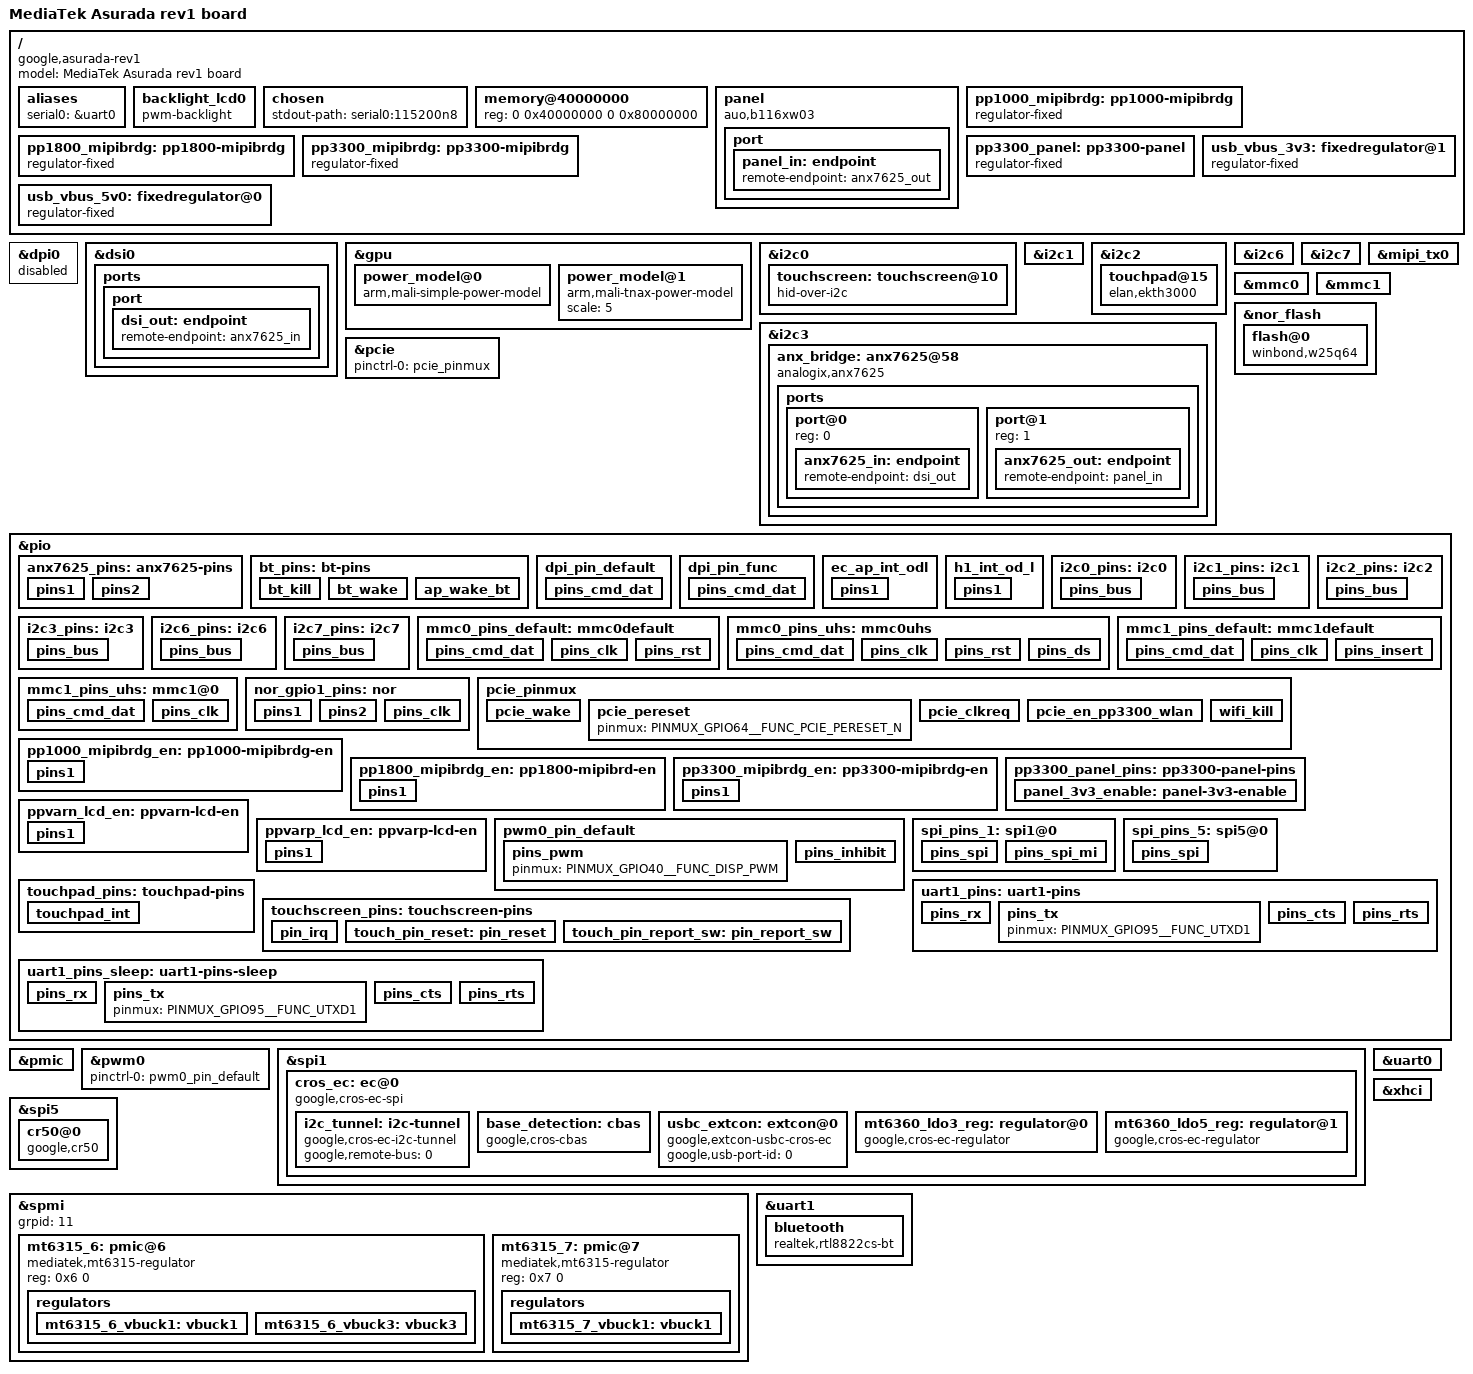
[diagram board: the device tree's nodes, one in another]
// SPDX-License-Identifier: (GPL-2.0 OR MIT)
/*
 * Copyright (C) 2020 MediaTek Inc.
 * Author: Seiya Wang <seiya.wang@mediatek.com>
 */
/dts-v1/;
#include <dt-bindings/gpio/gpio.h>
#include "mt8192.dtsi"
#include "mt6359.dtsi"

/ {
	model = "MediaTek Asurada rev1 board";
	compatible = "google,asurada-rev1", "google,asurada", "mediatek,mt6873";

	aliases {
		serial0 = &uart0;
	};

	backlight_lcd0: backlight_lcd0 {
		compatible = "pwm-backlight";
		pwms = <&pwm0 0 500000>;
		enable-gpios = <&pio 152 0>;
		brightness-levels = < 0 1023 >;
		num-interpolated-steps = <1023>;
		default-brightness-level = <576>;
		status = "okay";
	};

	chosen {
		stdout-path = "serial0:115200n8";
	};

	memory@40000000 {
		device_type = "memory";
		reg = <0 0x40000000 0 0x80000000>;
	};

	panel: panel {
		compatible = "auo,b116xw03";
		power-supply = <&pp3300_panel>;
		ddc-i2c-bus = <&i2c3>;
		backlight = <&backlight_lcd0>;

		port {
			panel_in: endpoint {
				remote-endpoint = <&anx7625_out>;
			};
		};
	};

	pp1000_mipibrdg: pp1000-mipibrdg {
		compatible = "regulator-fixed";
		regulator-name = "pp1000_mipibrdg";
		pinctrl-names = "default";
		pinctrl-0 = <&pp1000_mipibrdg_en>;

		enable-active-high;
		regulator-always-on;

		gpio = <&pio 129 GPIO_ACTIVE_HIGH>;
	};

	pp1800_mipibrdg: pp1800-mipibrdg {
		compatible = "regulator-fixed";
		regulator-name = "pp1800_mipibrdg";
		pinctrl-names = "default";
		pinctrl-0 = <&pp1800_mipibrdg_en>;

		enable-active-high;
		regulator-always-on;

		gpio = <&pio 128 GPIO_ACTIVE_HIGH>;
	};

	pp3300_mipibrdg: pp3300-mipibrdg {
		compatible = "regulator-fixed";
		regulator-name = "pp3300_mipibrdg";
		pinctrl-names = "default";
		pinctrl-0 = <&pp3300_mipibrdg_en>;

		enable-active-high;
		regulator-always-on;

		gpio = <&pio 127 GPIO_ACTIVE_HIGH>;
	};

	/* Probably useless, as we use pp3300_mipibrdg for panel power */
	pp3300_panel: pp3300-panel {
		compatible = "regulator-fixed";
		regulator-name = "pp3300_panel";
		regulator-min-microvolt = <3300000>;
		regulator-max-microvolt = <3300000>;
		pinctrl-names = "default";
		pinctrl-0 = <&pp3300_panel_pins>;

		enable-active-high;
		regulator-always-on;

		gpio = <&pio 136 GPIO_ACTIVE_HIGH>;
	};

	usb_vbus_3v3: fixedregulator@1 {
		compatible = "regulator-fixed";
		regulator-name = "usb vbus";
		regulator-min-microvolt = <3300000>;
		regulator-max-microvolt = <3300000>;
		regulator-always-on;
	};

	usb_vbus_5v0: fixedregulator@0 {
		compatible = "regulator-fixed";
		regulator-name = "vbus";
		regulator-min-microvolt = <5000000>;
		regulator-max-microvolt = <5000000>;
		regulator-type = "voltage";
		regulator-always-on;
	};
};

&dpi0 {
	pinctrl-names = "sleep", "default";
	pinctrl-0 = <&dpi_pin_default>;
	pinctrl-1 = <&dpi_pin_func>;
	status = "disabled";
};

&dsi0 {
	status = "okay";
	#address-cells = <1>;
	#size-cells = <0>;

	ports {
		port {
			dsi_out: endpoint {
				remote-endpoint = <&anx7625_in>;
			};
		};
	};
};

&gpu {
	supply-names = "mali","mali_sram";
	mali-supply = <&mt6315_7_vbuck1>;
	mali_sram-supply = <&mt6359_vsram_others_ldo_reg>;
	operating-points-v2 = <&gpu_opp_table>;
	power_model@0 {
		compatible = "arm,mali-simple-power-model";
		static-coefficient = <2427750>;
		dynamic-coefficient = <4687>;
		ts = <20000 2000 (-20) 2>;
		thermal-zone = "cpu_thermal";
	};
	power_model@1 {
		compatible = "arm,mali-tnax-power-model";
		scale = <5>;
	};
};

&i2c0 {
	pinctrl-names = "default";
	pinctrl-0 = <&i2c0_pins>;
	status = "okay";
	clock-frequency = <100000>;

	touchscreen: touchscreen@10 {
		compatible = "hid-over-i2c";
		reg = <0x10>;
		interrupt-parent = <&pio>;
		interrupts = <21 IRQ_TYPE_LEVEL_LOW>;

		pinctrl-names = "default";
		pinctrl-0 = <&touchscreen_pins>;

		post-power-on-delay-ms = <10>;
		hid-descr-addr = <0x0001>;
	};
};

&i2c1 {
	pinctrl-names = "default";
	pinctrl-0 = <&i2c1_pins>;
	status = "okay";
	clock-frequency = <100000>;

	/* TODO: Add audio components */
};

&i2c2 {
	pinctrl-names = "default";
	pinctrl-0 = <&i2c2_pins>;
	status = "okay";
	clock-frequency = <100000>;

	touchpad@15 {
		compatible = "elan,ekth3000";
		reg = <0x15>;

		pinctrl-names = "default";
		pinctrl-0 = <&touchpad_pins>;

		interrupt-parent = <&pio>;
		interrupts = <15 IRQ_TYPE_LEVEL_LOW>;

		wakeup-source;
	};

};

&i2c3 {
	pinctrl-names = "default";
	pinctrl-0 = <&i2c3_pins>;
	status = "okay";
	clock-frequency = <100000>;

	anx_bridge: anx7625@58 {
		compatible = "analogix,anx7625";
		reg = <0x58>;
		pinctrl-names = "default";
		pinctrl-0 = <&anx7625_pins>;
		panel_flags = <1>;
		enable-gpios = <&pio 41 GPIO_ACTIVE_HIGH>;
		reset-gpios = <&pio 42 GPIO_ACTIVE_HIGH>;
		vdd10-supply = <&pp1000_mipibrdg>;
		vdd18-supply = <&pp1800_mipibrdg>;
		vdd33-supply = <&pp3300_mipibrdg>;

		ports {
			#address-cells = <1>;
			#size-cells = <0>;
			port@0 {
				reg = <0>;
				anx7625_in: endpoint {
					remote-endpoint = <&dsi_out>;
				};
			};

			port@1 {
				reg = <1>;
				anx7625_out: endpoint {
					remote-endpoint = <&panel_in>;
				};
			};
		};
	};
};

&i2c6 {
	pinctrl-names = "default";
	pinctrl-0 = <&i2c6_pins>;
	status = "okay";
	clock-frequency = <100000>;

	/* TODO: Add SAR sensor. */
};

&i2c7 {
	pinctrl-names = "default";
	pinctrl-0 = <&i2c7_pins>;
	status = "okay";
	clock-frequency = <100000>;

	/* TODO: Add ANX7625 external DP bridge. */
};

&mipi_tx0 {
	status = "okay";
};

&mmc0 {
	status = "okay";
	pinctrl-names = "default", "state_uhs";
	pinctrl-0 = <&mmc0_pins_default>;
	pinctrl-1 = <&mmc0_pins_uhs>;
	bus-width = <8>;
	max-frequency = <200000000>;
	cap-mmc-highspeed;
	mmc-hs200-1_8v;
	mmc-hs400-1_8v;
	supports-cqe;
	cap-mmc-hw-reset;
	hs400-ds-delay = <0x12814>;
	no-sdio;
	no-sd;
	vmmc-supply = <&mt6359_vemc_1_ldo_reg>;
	vqmmc-supply = <&mt6359_vufs_ldo_reg>;
	non-removable;
};

&mmc1 {
	status = "okay";
	pinctrl-names = "default", "state_uhs";
	pinctrl-0 = <&mmc1_pins_default>;
	pinctrl-1 = <&mmc1_pins_uhs>;
	bus-width = <4>;
	max-frequency = <200000000>;
	cap-sd-highspeed;
	sd-uhs-sdr50;
	sd-uhs-sdr104;
	cd-gpios = <&pio 17 GPIO_ACTIVE_LOW>;
	vmmc-supply = <&mt6360_ldo5_reg>;
	vqmmc-supply = <&mt6360_ldo3_reg>;
	no-mmc;
	no-sdio;
};

&nor_flash {
	status = "okay";
	pinctrl-names = "default";
	pinctrl-0 = <&nor_gpio1_pins>;
	assigned-clocks = <&topckgen CLK_TOP_SFLASH_SEL>;
	assigned-clock-parents = <&topckgen CLK_TOP_UNIVPLL_D6_D8>;

	flash@0 {
		compatible = "winbond,w25q64", "jedec,spi-nor";
		reg = <0>;
		spi-max-frequency = <52000000>;
		spi-rx-bus-width = <2>;
		spi-tx-bus-width = <2>;
	};
};

&pcie {
	status = "okay";
	pinctrl-names = "default";
	pinctrl-0 = <&pcie_pinmux>;
};

&pio {
	anx7625_pins: anx7625-pins {
		pins1 {
			pinmux = <PINMUX_GPIO41__FUNC_GPIO41>,
				 <PINMUX_GPIO42__FUNC_GPIO42>;
			output-low;
		};
		pins2 {
			pinmux = <PINMUX_GPIO6__FUNC_GPIO6>;
			input-enable;
			bias-pull-up;
		};
	};

	bt_pins: bt-pins {
		bt_kill: bt_kill {
			pinmux = <PINMUX_GPIO131__FUNC_GPIO131>; /* BT_KILL_L */
			output-low;
		};
		bt_wake: bt_wake {
			pinmux = <PINMUX_GPIO22__FUNC_GPIO22>;  /* bt to wake ap */
			bias-pull-up;
		};
		ap_wake_bt: ap_wake_bt {
			pinmux = <PINMUX_GPIO168__FUNC_GPIO168>; /* AP_WAKE_BT_L */
			output-low;
		};
	};

	dpi_pin_default: dpi_pin_default {
		pins_cmd_dat {
			pinmux = <PINMUX_GPIO96__FUNC_GPIO96>,
				<PINMUX_GPIO97__FUNC_GPIO97>,
				<PINMUX_GPIO98__FUNC_GPIO98>,
				<PINMUX_GPIO99__FUNC_GPIO99>,
				<PINMUX_GPIO100__FUNC_GPIO100>,
				<PINMUX_GPIO101__FUNC_GPIO101>,
				<PINMUX_GPIO102__FUNC_GPIO102>,
				<PINMUX_GPIO103__FUNC_GPIO103>,
				<PINMUX_GPIO104__FUNC_GPIO104>,
				<PINMUX_GPIO105__FUNC_GPIO105>,
				<PINMUX_GPIO106__FUNC_GPIO106>,
				<PINMUX_GPIO110__FUNC_GPIO110>,
				<PINMUX_GPIO113__FUNC_GPIO113>,
				<PINMUX_GPIO111__FUNC_GPIO111>,
				<PINMUX_GPIO109__FUNC_GPIO109>,
				<PINMUX_GPIO112__FUNC_GPIO112>;
				drive-strength = <MTK_DRIVE_6mA>;
				output-low;
		};
	};

	dpi_pin_func: dpi_pin_func {
		pins_cmd_dat {
			pinmux = <PINMUX_GPIO96__FUNC_DPI_D0>,
				<PINMUX_GPIO97__FUNC_DPI_D1>,
				<PINMUX_GPIO98__FUNC_DPI_D2>,
				<PINMUX_GPIO99__FUNC_DPI_D3>,
				<PINMUX_GPIO100__FUNC_DPI_D4>,
				<PINMUX_GPIO101__FUNC_DPI_D5>,
				<PINMUX_GPIO102__FUNC_DPI_D6>,
				<PINMUX_GPIO103__FUNC_DPI_D7>,
				<PINMUX_GPIO104__FUNC_DPI_D8>,
				<PINMUX_GPIO105__FUNC_DPI_D9>,
				<PINMUX_GPIO106__FUNC_DPI_D10>,
				<PINMUX_GPIO110__FUNC_DPI_D11>,
				<PINMUX_GPIO113__FUNC_DPI_HSYNC>,
				<PINMUX_GPIO111__FUNC_DPI_VSYNC>,
				<PINMUX_GPIO109__FUNC_DPI_DE>,
				<PINMUX_GPIO112__FUNC_DPI_CK>;
				drive-strength = <MTK_DRIVE_6mA>;
		};
	};

	ec_ap_int_odl: ec_ap_int_odl {
		pins1 {
			pinmux = <PINMUX_GPIO5__FUNC_GPIO5>;
			input-enable;
			bias-pull-up;
		};
	};

	h1_int_od_l: h1_int_od_l {
		pins1 {
			pinmux = <PINMUX_GPIO171__FUNC_GPIO171>;
			input-enable;
		};
	};

	i2c0_pins: i2c0 {
		pins_bus {
			pinmux = <PINMUX_GPIO204__FUNC_SCL0>,
				 <PINMUX_GPIO205__FUNC_SDA0>;
			bias-pull-up;
			mediatek,pull-up-adv = <3>;
			mediatek,drive-strength-adv = <7>;
		};
	};

	i2c1_pins: i2c1 {
		pins_bus {
			pinmux = <PINMUX_GPIO118__FUNC_SCL1>,
				 <PINMUX_GPIO119__FUNC_SDA1>;
			bias-pull-up;
			mediatek,pull-up-adv = <3>;
			mediatek,drive-strength-adv = <7>;
		};
	};

	i2c2_pins: i2c2 {
		pins_bus {
			pinmux = <PINMUX_GPIO141__FUNC_SCL2>,
				 <PINMUX_GPIO142__FUNC_SDA2>;
			bias-pull-up;
			mediatek,pull-up-adv = <3>;
			mediatek,drive-strength-adv = <7>;
		};
	};

	i2c3_pins: i2c3 {
		pins_bus {
			pinmux = <PINMUX_GPIO160__FUNC_SCL3>,
				 <PINMUX_GPIO161__FUNC_SDA3>;
			bias-pull-up;
			mediatek,pull-up-adv = <3>;
			mediatek,drive-strength-adv = <7>;
		};
	};

	i2c6_pins: i2c6 {
		pins_bus {
			pinmux = <PINMUX_GPIO200__FUNC_SCL6>,
				 <PINMUX_GPIO201__FUNC_SDA6>;
			bias-pull-up;
			mediatek,pull-up-adv = <3>;
			mediatek,drive-strength-adv = <7>;
		};
	};

	i2c7_pins: i2c7 {
		pins_bus {
			pinmux = <PINMUX_GPIO124__FUNC_SCL7>,
				 <PINMUX_GPIO125__FUNC_SDA7>;
			bias-pull-up;
			mediatek,pull-up-adv = <3>;
			mediatek,drive-strength-adv = <7>;
		};
	};

	mmc0_pins_default: mmc0default {
		pins_cmd_dat {
			pinmux = <PINMUX_GPIO184__FUNC_MSDC0_DAT0>,
				 <PINMUX_GPIO188__FUNC_MSDC0_DAT1>,
				 <PINMUX_GPIO185__FUNC_MSDC0_DAT2>,
				 <PINMUX_GPIO193__FUNC_MSDC0_DAT3>,
				 <PINMUX_GPIO186__FUNC_MSDC0_DAT4>,
				 <PINMUX_GPIO189__FUNC_MSDC0_DAT5>,
				 <PINMUX_GPIO187__FUNC_MSDC0_DAT6>,
				 <PINMUX_GPIO190__FUNC_MSDC0_DAT7>,
				 <PINMUX_GPIO183__FUNC_MSDC0_CMD>;
			input-enable;
			drive-strength = <3>;
			mediatek,pull-up-adv = <1>;
		};

		pins_clk {
			pinmux = <PINMUX_GPIO192__FUNC_MSDC0_CLK>;
			drive-strength = <3>;
			mediatek,pull-down-adv = <2>;
		};

		pins_rst {
			pinmux = <PINMUX_GPIO194__FUNC_MSDC0_RSTB>;
			drive-strength = <3>;
			mediatek,pull-down-adv = <1>;
		};
	};

	mmc0_pins_uhs: mmc0uhs{
		pins_cmd_dat {
			pinmux = <PINMUX_GPIO184__FUNC_MSDC0_DAT0>,
				 <PINMUX_GPIO188__FUNC_MSDC0_DAT1>,
				 <PINMUX_GPIO185__FUNC_MSDC0_DAT2>,
				 <PINMUX_GPIO193__FUNC_MSDC0_DAT3>,
				 <PINMUX_GPIO186__FUNC_MSDC0_DAT4>,
				 <PINMUX_GPIO189__FUNC_MSDC0_DAT5>,
				 <PINMUX_GPIO187__FUNC_MSDC0_DAT6>,
				 <PINMUX_GPIO190__FUNC_MSDC0_DAT7>,
				 <PINMUX_GPIO183__FUNC_MSDC0_CMD>;
			input-enable;
			drive-strength = <4>;
			mediatek,pull-up-adv = <1>;
		};

		pins_clk {
			pinmux = <PINMUX_GPIO192__FUNC_MSDC0_CLK>;
			drive-strength = <4>;
			mediatek,pull-down-adv = <2>;
		};

		pins_rst {
			pinmux = <PINMUX_GPIO194__FUNC_MSDC0_RSTB>;
			drive-strength = <3>;
			mediatek,pull-down-adv = <1>;
		};

		pins_ds {
			pinmux = <PINMUX_GPIO191__FUNC_MSDC0_DSL>;
			drive-strength = <4>;
			mediatek,pull-down-adv = <2>;
		};
	};

	mmc1_pins_default: mmc1default {
		pins_cmd_dat {
			pinmux = <PINMUX_GPIO54__FUNC_MSDC1_DAT0>,
				 <PINMUX_GPIO56__FUNC_MSDC1_DAT1>,
				 <PINMUX_GPIO55__FUNC_MSDC1_DAT2>,
				 <PINMUX_GPIO53__FUNC_MSDC1_DAT3>,
				 <PINMUX_GPIO52__FUNC_MSDC1_CMD>;
			input-enable;
			drive-strength = <3>;
			mediatek,pull-up-adv = <1>;
		};

		pins_clk {
			pinmux = <PINMUX_GPIO51__FUNC_MSDC1_CLK>;
			drive-strength = <3>;
			mediatek,pull-down-adv = <2>;
		};

		pins_insert {
			pinmux = <PINMUX_GPIO17__FUNC_GPIO17>;
			input-enable;
			bias-pull-up;
		};
	};

	mmc1_pins_uhs: mmc1@0 {
		pins_cmd_dat {
			pinmux = <PINMUX_GPIO54__FUNC_MSDC1_DAT0>,
				 <PINMUX_GPIO56__FUNC_MSDC1_DAT1>,
				 <PINMUX_GPIO55__FUNC_MSDC1_DAT2>,
				 <PINMUX_GPIO53__FUNC_MSDC1_DAT3>,
				 <PINMUX_GPIO52__FUNC_MSDC1_CMD>;
			input-enable;
			drive-strength = <3>;
			mediatek,pull-up-adv = <1>;
		};

		pins_clk {
			pinmux = <PINMUX_GPIO51__FUNC_MSDC1_CLK>;
			drive-strength = <3>;
			mediatek,pull-down-adv = <2>;
			input-enable;
		};
	};

	nor_gpio1_pins: nor {
		pins1 {
			pinmux = <PINMUX_GPIO24__FUNC_SPINOR_CS>,
				 <PINMUX_GPIO28__FUNC_SPINOR_IO1>;
			input-enable;
			drive-strength = <MTK_DRIVE_4mA>;
			bias-pull-up;
		};

		pins2 {
			pinmux = <PINMUX_GPIO27__FUNC_SPINOR_IO0>;
			drive-strength = <MTK_DRIVE_4mA>;
			bias-pull-up;
		};

		pins_clk {
			pinmux = <PINMUX_GPIO25__FUNC_SPINOR_CK>;
			input-enable;
			drive-strength = <MTK_DRIVE_4mA>;
			bias-pull-up;
		};
	};

	pcie_pinmux: pcie_pinmux {
		pcie_wake {
			pinmux = <PINMUX_GPIO63__FUNC_PCIE_WAKE_N>;
			bias-pull-up;
		};
		pcie_pereset {
			pinmux = <PINMUX_GPIO64__FUNC_PCIE_PERESET_N>;
		};
		pcie_clkreq {
			pinmux = <PINMUX_GPIO65__FUNC_PCIE_CLKREQ_N>;
			bias-pull-up;
		};
		pcie_en_pp3300_wlan {
			/* TODO: Model as a regulator */
			pinmux = <PINMUX_GPIO130__FUNC_GPIO130>;
			output-high;
		};
		/* TODO: Split and implement. */
		wifi_kill {
			pinmux = <PINMUX_GPIO132__FUNC_GPIO132>; /* WIFI_KILL_L */
			output-high;
		};
	};

	pp1000_mipibrdg_en: pp1000-mipibrdg-en {
		pins1 {
			pinmux = <PINMUX_GPIO129__FUNC_GPIO129>;
			output-low;
		};
	};

	pp1800_mipibrdg_en: pp1800-mipibrd-en {
		pins1 {
			pinmux = <PINMUX_GPIO128__FUNC_GPIO128>;
			output-low;
		};
	};

	pp3300_mipibrdg_en: pp3300-mipibrdg-en {
		pins1 {
			pinmux = <PINMUX_GPIO127__FUNC_GPIO127>;
			output-low;
		};
	};

	pp3300_panel_pins: pp3300-panel-pins {
		panel_3v3_enable: panel-3v3-enable {
			pinmux = <PINMUX_GPIO136__FUNC_GPIO136>;
			output-low;
		};
	};

	ppvarn_lcd_en: ppvarn-lcd-en {
		pins1 {
			pinmux = <PINMUX_GPIO166__FUNC_GPIO166>;
			output-low;
		};
	};

	ppvarp_lcd_en: ppvarp-lcd-en {
		pins1 {
			pinmux = <PINMUX_GPIO66__FUNC_GPIO66>;
			output-low;
		};
	};

	pwm0_pin_default: pwm0_pin_default {
		pins_pwm {
			pinmux = <PINMUX_GPIO40__FUNC_DISP_PWM>;
		};
		pins_inhibit {
			pinmux = <PINMUX_GPIO152__FUNC_GPIO152>;
			output-high;
		};
	};

	spi_pins_1: spi1@0 {
		pins_spi{
			pinmux = <PINMUX_GPIO157__FUNC_SPI1_A_CSB>,
				 <PINMUX_GPIO159__FUNC_SPI1_A_MO>,
				 <PINMUX_GPIO156__FUNC_SPI1_A_CLK>;
			bias-disable;
		};
		pins_spi_mi {
			pinmux = <PINMUX_GPIO158__FUNC_SPI1_A_MI>;
			bias-pull-down;
		};
	};

	spi_pins_5: spi5@0 {
		pins_spi{
			pinmux = <PINMUX_GPIO38__FUNC_SPI5_A_MI>,
				 <PINMUX_GPIO37__FUNC_GPIO37>,
				 <PINMUX_GPIO39__FUNC_SPI5_A_MO>,
				 <PINMUX_GPIO36__FUNC_SPI5_A_CLK>;
			bias-disable;
		};
	};

	touchpad_pins: touchpad-pins {
		touchpad_int {
			pinmux = <PINMUX_GPIO15__FUNC_GPIO15>;
			input-enable;
			mediatek,pull-up-adv = <3>;
		};
	};

	touchscreen_pins: touchscreen-pins {
		pin_irq {
			pinmux = <PINMUX_GPIO21__FUNC_GPIO21>;
			input-enable;
			bias-pull-up;
		};
		touch_pin_reset: pin_reset {
			pinmux = <PINMUX_GPIO137__FUNC_GPIO137>;
			output-high;
		};
		touch_pin_report_sw: pin_report_sw {
			pinmux = <PINMUX_GPIO138__FUNC_GPIO138>;
			output-low;
		};
	};

	uart1_pins: uart1-pins {
		pins_rx {
			pinmux = <PINMUX_GPIO94__FUNC_URXD1>;
			input-enable;
			bias-pull-up;
		};
		pins_tx {
			pinmux = <PINMUX_GPIO95__FUNC_UTXD1>;
		};
		pins_cts {
			pinmux = <PINMUX_GPIO166__FUNC_UCTS1>;
			output-enable;
		};
		pins_rts {
			pinmux = <PINMUX_GPIO167__FUNC_URTS1>;
			input-enable;
		};
	};

	uart1_pins_sleep: uart1-pins-sleep {
		pins_rx {
			pinmux = <PINMUX_GPIO94__FUNC_GPIO94>;
			input-enable;
			bias-pull-up;
		};
		pins_tx {
			pinmux = <PINMUX_GPIO95__FUNC_UTXD1>;
		};
		pins_cts {
			pinmux = <PINMUX_GPIO166__FUNC_UCTS1>;
			output-enable;
		};
		pins_rts {
			pinmux = <PINMUX_GPIO167__FUNC_URTS1>;
			input-enable;
		};
	};
};

&pmic {
	interrupt-parent = <&pio>;
	interrupts = <214 IRQ_TYPE_LEVEL_HIGH>;
};

&pwm0 {
	status = "okay";
	pinctrl-names = "default";
	pinctrl-0 = <&pwm0_pin_default>;
};

&spi1 {
	pinctrl-names = "default";
	pinctrl-0 = <&spi_pins_1>;
	mediatek,pad-select = <0>;
	status = "okay";

	cros_ec: ec@0 {
		compatible = "google,cros-ec-spi";
		reg = <0>;
		spi-max-frequency = <3000000>;
		interrupt-parent = <&pio>;
		interrupts = <5 IRQ_TYPE_LEVEL_LOW>;
		pinctrl-names = "default";
		pinctrl-0 = <&ec_ap_int_odl>;

		#address-cells = <1>;
		#size-cells = <0>;

		i2c_tunnel: i2c-tunnel {
			compatible = "google,cros-ec-i2c-tunnel";
			google,remote-bus = <0>;
			#address-cells = <1>;
			#size-cells = <0>;
		};

		base_detection: cbas {
			compatible = "google,cros-cbas";
		};

		usbc_extcon: extcon@0 {
			compatible = "google,extcon-usbc-cros-ec";
			google,usb-port-id = <0>;
			#extcon-cells = <0>;
		};

		mt6360_ldo3_reg: regulator@0 {
			compatible = "google,cros-ec-regulator";
			regulator-min-microvolt = <1800000>;
			regulator-max-microvolt = <3300000>;
			reg = <0>;
		};

		mt6360_ldo5_reg: regulator@1 {
			compatible = "google,cros-ec-regulator";
			regulator-min-microvolt = <3300000>;
			regulator-max-microvolt = <3300000>;
			reg = <1>;
		};
	};
};

&spi5 {
	pinctrl-names = "default";
	pinctrl-0 = <&spi_pins_5>;
	mediatek,pad-select = <0>;
	status = "okay";
	cs-gpios = <&pio 37 GPIO_ACTIVE_LOW>;

	cr50@0 {
		compatible = "google,cr50";
		reg = <0>;
		spi-max-frequency = <1000000>;
		pinctrl-names = "default";
		pinctrl-0 = <&h1_int_od_l>;
		interrupt-parent = <&pio>;
		interrupts = <171 IRQ_TYPE_EDGE_RISING>;
	};
};

&spmi {
	grpid = <11>;
	mt6315_6: pmic@6 {
		compatible = "mediatek,mt6315-regulator";
		reg = <0x6 0>;

		regulators {
			mt6315_6_vbuck1: vbuck1 {
				regulator-compatible = "vbuck1";
				regulator-name = "Vbcpu";
				regulator-min-microvolt = <300000>;
				regulator-max-microvolt = <1193750>;
				regulator-enable-ramp-delay = <256>;
				regulator-allowed-modes = <0 1 2 4>;
				regulator-always-on;
			};

			mt6315_6_vbuck3: vbuck3 {
				regulator-compatible = "vbuck3";
				regulator-name = "Vlcpu";
				regulator-min-microvolt = <300000>;
				regulator-max-microvolt = <1193750>;
				regulator-enable-ramp-delay = <256>;
				regulator-allowed-modes = <0 1 2 4>;
				regulator-always-on;
			};
		};
	};

	mt6315_7: pmic@7 {
		compatible = "mediatek,mt6315-regulator";
		reg = <0x7 0>;

		regulators {
			mt6315_7_vbuck1: vbuck1 {
				regulator-compatible = "vbuck1";
				regulator-name = "Vgpu";
				regulator-min-microvolt = <300000>;
				regulator-max-microvolt = <1193750>;
				regulator-enable-ramp-delay = <256>;
				regulator-allowed-modes = <0 1 2 4>;
			};
		};
	};
};

&uart0 {
	status = "okay";
};

&uart1 {
	status = "okay";
	pinctrl-names = "default", "sleep";
	pinctrl-0 = <&uart1_pins>;
	pinctrl-1 = <&uart1_pins_sleep>;
	interrupts-extended = <&gic GIC_SPI 110 IRQ_TYPE_LEVEL_HIGH 0>,
			      <&pio 94 IRQ_TYPE_EDGE_FALLING>;

	bluetooth {
		compatible = "realtek,rtl8822cs-bt";
		pinctrl-names = "default";
		pinctrl-0 = <&bt_pins>;

		enable-gpios = <&pio 131 GPIO_ACTIVE_HIGH>;
	};
};

&xhci {
	vusb33-supply = <&usb_vbus_3v3>;
	vbus-supply = <&usb_vbus_5v0>;
	wakeup-source;
	status = "okay";
};

#include <arm/cros-ec-keyboard.dtsi>
#include <arm/cros-ec-sbs.dtsi>
